# LM3S6965 register map
Vendor: Texas Instruments; File version: 0.1.0
CPU: Cortex-M3 r2p2, little endian, MPU, no FPU, VTOR, 3 interrupt priority bits
Registers are 32-bit, read-write, no defined reset value unless marked. A register's access mark holds for its fields unless they carry their own. Offsets are from the block's base; [hi:lo] are bit positions.

## WATCHDOG0 — 32-bit watchdog timer with first-timeout interrupt and second-timeout reset support.
Base 0x40000000
0x00 LOAD — Watchdog Load
  [31:0] LOAD — Watchdog load value.
0x04 VALUE — Watchdog Value
  [31:0] VALUE ro — Current watchdog counter value.
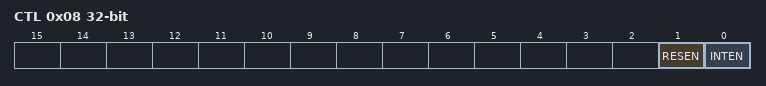
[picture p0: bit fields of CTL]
0x08 CTL — Watchdog Control
  [1] RESEN — Reset enable on second timeout.
  [0] INTEN — Interrupt enable.
0x0C ICR — Watchdog Interrupt Clear
  [0] INTCLR — Clears the watchdog interrupt.
0x10 RIS — Watchdog Raw Interrupt Status
  [0] WDRIS ro — Raw watchdog interrupt status.
0x14 MIS — Watchdog Masked Interrupt Status
  [0] WDMIS ro — Masked watchdog interrupt status.
0x418 TEST — Watchdog Test
0xC00 LOCK — Watchdog Lock

## GPIOA — General-purpose I/O port A.
Base 0x40004000
0x3FC DATA — GPIO Data
  [7:0] GPIO — GPIO Data bits for GPIO[7:0].
0x400 DIR — GPIO Direction
  [7:0] GPIO — GPIO Direction bits for GPIO[7:0].
0x404 IS — GPIO Interrupt Sense
  [7:0] GPIO — GPIO Interrupt Sense bits for GPIO[7:0].
0x408 IBE — GPIO Interrupt Both Edges
  [7:0] GPIO — GPIO Interrupt Both Edges bits for GPIO[7:0].
0x40C IEV — GPIO Interrupt Event
  [7:0] GPIO — GPIO Interrupt Event bits for GPIO[7:0].
0x410 IM — GPIO Interrupt Mask
  [7:0] GPIO — GPIO Interrupt Mask bits for GPIO[7:0].
0x414 RIS — GPIO Raw Interrupt Status
  [7:0] GPIO — GPIO Raw Interrupt Status bits for GPIO[7:0].
0x418 MIS — GPIO Masked Interrupt Status
  [7:0] GPIO — GPIO Masked Interrupt Status bits for GPIO[7:0].
0x41C ICR — GPIO Interrupt Clear
  [7:0] GPIO — GPIO Interrupt Clear bits for GPIO[7:0].
0x420 AFSEL — GPIO Alternate Function Select
  [7:0] GPIO — GPIO Alternate Function Select bits for GPIO[7:0].
0x500 DR2R — GPIO 2-mA Drive Select
  [7:0] GPIO — GPIO 2-mA Drive Select bits for GPIO[7:0].
0x504 DR4R — GPIO 4-mA Drive Select
  [7:0] GPIO — GPIO 4-mA Drive Select bits for GPIO[7:0].
0x508 DR8R — GPIO 8-mA Drive Select
  [7:0] GPIO — GPIO 8-mA Drive Select bits for GPIO[7:0].
0x50C ODR — GPIO Open Drain Select
  [7:0] GPIO — GPIO Open Drain Select bits for GPIO[7:0].
0x510 PUR — GPIO Pull-Up Select
  [7:0] GPIO — GPIO Pull-Up Select bits for GPIO[7:0].
0x514 PDR — GPIO Pull-Down Select
  [7:0] GPIO — GPIO Pull-Down Select bits for GPIO[7:0].
0x518 SLR — GPIO Slew Rate Control Select
  [7:0] GPIO — GPIO Slew Rate Control Select bits for GPIO[7:0].
0x51C DEN — GPIO Digital Enable
  [7:0] GPIO — GPIO Digital Enable bits for GPIO[7:0].
0x520 LOCK — GPIO Lock
0x524 CR ro — GPIO Commit
  [7:0] GPIO — GPIO Commit bits for GPIO[7:0].

## GPIOB — General-purpose I/O port B.
Base 0x40005000
Same registers: GPIOC 0x40006000, GPIOD 0x40007000, GPIOE 0x40024000, GPIOF 0x40025000
Registers as GPIOA; these are added or differ:
0x41C ICR wo — GPIO Interrupt Clear
  [7:0] GPIO — GPIO Interrupt Clear bits for GPIO[7:0].

## SSI0 — Synchronous serial interface 0.
Base 0x40008000
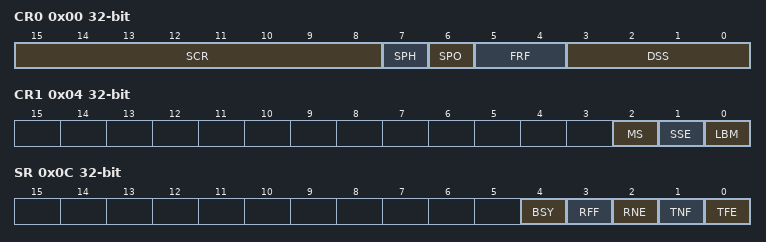
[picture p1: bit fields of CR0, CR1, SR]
0x00 CR0 — SSI Control 0
  [15:8] SCR — Serial clock rate.
  [7] SPH — Serial clock phase.
  [6] SPO — Serial clock polarity.
  [5:4] FRF — Frame format.
  [3:0] DSS — Data size select.
0x04 CR1 — SSI Control 1
  [2] MS — Master/slave select.
  [1] SSE — SSI enable.
  [0] LBM — Loopback mode.
0x08 DR — SSI Data
  [15:0] DATA — Transmit/receive data.
0x0C SR — SSI Status
  [4] BSY ro — SSI busy.
  [3] RFF ro — Receive FIFO full.
  [2] RNE ro — Receive FIFO not empty.
  [1] TNF ro — Transmit FIFO not full.
  [0] TFE ro — Transmit FIFO empty.
0x10 CPSR — SSI Clock Prescale
  [7:0] CPSDVSR — Clock prescale divisor.
0x14 IM — SSI Interrupt Mask
0x18 RIS — SSI Raw Interrupt Status
0x1C MIS — SSI Masked Interrupt Status
0x20 ICR wo — SSI Interrupt Clear
